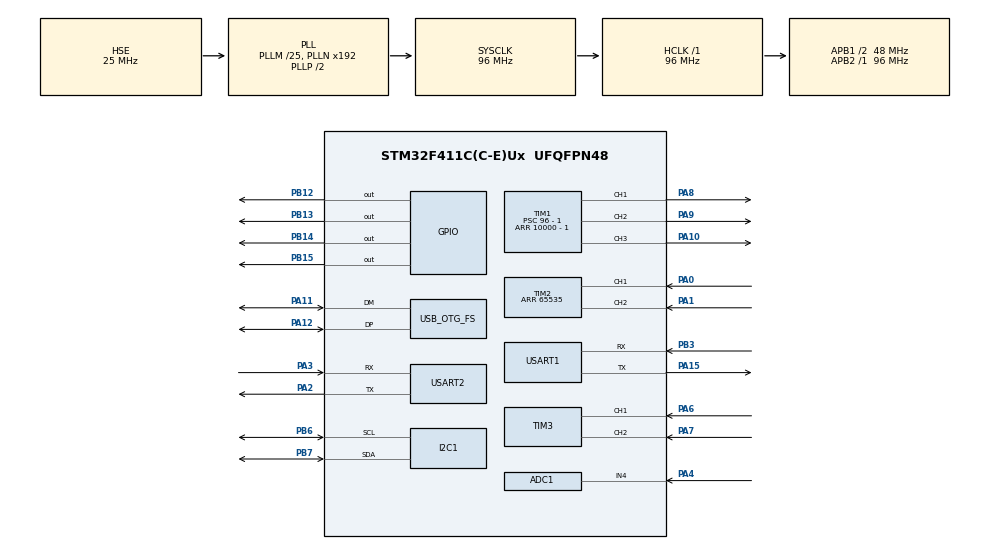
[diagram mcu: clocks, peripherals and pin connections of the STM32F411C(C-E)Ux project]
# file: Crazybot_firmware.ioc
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ADC1.Channel-0\#ChannelRegularConversion=ADC_CHANNEL_4
ADC1.NbrOfConversionFlag=1
ADC1.Rank-0\#ChannelRegularConversion=1
ADC1.SamplingTime-0\#ChannelRegularConversion=ADC_SAMPLETIME_3CYCLES
ADC1.master=1
I2C1.I2C_Mode=I2C_Fast
Mcu.Family=STM32F4
Mcu.Name=STM32F411C(C-E)Ux
Mcu.Package=UFQFPN48
NVIC.PriorityGroup=NVIC_PRIORITYGROUP_4
PA0-WKUP.Signal=S_TIM2_CH1_ETR
PA1.Signal=S_TIM2_CH2
PA10.Signal=S_TIM1_CH3
PA11.Mode=Device_Only
PA11.Signal=USB_OTG_FS_DM
PA12.Mode=Device_Only
PA12.Signal=USB_OTG_FS_DP
PA13.Mode=Serial_Wire
PA13.Signal=SYS_JTMS-SWDIO
PA14.Mode=Serial_Wire
PA14.Signal=SYS_JTCK-SWCLK
PA15.Mode=Asynchronous
PA15.Signal=USART1_TX
PA2.Mode=Asynchronous
PA2.Signal=USART2_TX
PA3.Mode=Asynchronous
PA3.Signal=USART2_RX
PA4.Signal=ADCx_IN4
PA6.Signal=S_TIM3_CH1
PA7.Signal=S_TIM3_CH2
PA8.Signal=S_TIM1_CH1
PA9.Signal=S_TIM1_CH2
PB12.Signal=GPIO_Output
PB13.Signal=GPIO_Output
PB14.Signal=GPIO_Output
PB15.Signal=GPIO_Output
PB3.Mode=Asynchronous
PB3.Signal=USART1_RX
PB6.Mode=I2C
PB6.Signal=I2C1_SCL
PB7.Mode=I2C
PB7.Signal=I2C1_SDA
PH0\ -\ OSC_IN.Mode=HSE-External-Oscillator
PH0\ -\ OSC_IN.Signal=RCC_OSC_IN
PH1\ -\ OSC_OUT.Mode=HSE-External-Oscillator
PH1\ -\ OSC_OUT.Signal=RCC_OSC_OUT
ProjectManager.HeapSize=0x200
ProjectManager.StackSize=0x400
ProjectManager.TargetToolchain=Makefile
RCC.48MHZClocksFreq_Value=48000000
RCC.AHBFreq_Value=96000000
RCC.APB1CLKDivider=RCC_HCLK_DIV2
RCC.APB1Freq_Value=48000000
RCC.APB1TimFreq_Value=96000000
RCC.APB2Freq_Value=96000000
RCC.APB2TimFreq_Value=96000000
RCC.CortexFreq_Value=96000000
RCC.HCLKFreq_Value=96000000
RCC.HSE_VALUE=25000000
RCC.HSI_VALUE=16000000
RCC.LSE_VALUE=32768
RCC.PLLM=25
RCC.SYSCLKFreq_VALUE=96000000
RCC.SYSCLKSource=RCC_SYSCLKSOURCE_PLLCLK
RCC.VCOOutputFreq_Value=192000000
SH.ADCx_IN4.0=ADC1_IN4,IN4
SH.S_TIM1_CH1.0=TIM1_CH1,PWM Generation1 CH1
SH.S_TIM1_CH2.0=TIM1_CH2,PWM Generation2 CH2
SH.S_TIM1_CH3.0=TIM1_CH3,PWM Generation3 CH3
SH.S_TIM2_CH1_ETR.0=TIM2_CH1,Encoder_Interface
SH.S_TIM2_CH2.0=TIM2_CH2,Encoder_Interface
SH.S_TIM3_CH1.0=TIM3_CH1,Encoder_Interface
SH.S_TIM3_CH2.0=TIM3_CH2,Encoder_Interface
TIM1.Channel-PWM\ Generation1\ CH1=TIM_CHANNEL_1
TIM1.Channel-PWM\ Generation2\ CH2=TIM_CHANNEL_2
TIM1.Channel-PWM\ Generation3\ CH3=TIM_CHANNEL_3
TIM1.Period=10000 - 1
TIM1.Prescaler=96 - 1
TIM2.EncoderMode=TIM_ENCODERMODE_TI12
TIM2.IC1Filter=15
TIM2.IC2Filter=15
TIM2.Period=65535
TIM3.EncoderMode=TIM_ENCODERMODE_TI12
TIM3.IC1Filter=15
TIM3.IC2Filter=15
USART1.VirtualMode=VM_ASYNC
USART2.VirtualMode=VM_ASYNC
USB_OTG_FS.VirtualMode=Device_Only
VP_TIM1_VS_ClockSourceINT.Mode=Internal
board=custom

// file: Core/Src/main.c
/* USER CODE BEGIN Header */
/**
  ******************************************************************************
  * @file           : main.c
  * @brief          : Main program body
  ******************************************************************************
  * @attention
  *
  * Copyright (c) 2023 STMicroelectronics.
  * All rights reserved.
  *
  * This software is licensed under terms that can be found in the LICENSE file
  * in the root directory of this software component.
  * If no LICENSE file comes with this software, it is provided AS-IS.
  *
  ******************************************************************************
  */
/* USER CODE END Header */
#include "main.h"
#include "adc.h"
#include "i2c.h"
#include "tim.h"
#include "usart.h"
#include "usb_otg.h"
#include "gpio.h"

/* USER CODE BEGIN Includes */
#include <stdio.h>
/* USER CODE END Includes */

void SystemClock_Config(void);

int main(void)
{

  /* MCU Configuration--------------------------------------------------------*/

  /* Reset of all peripherals, Initializes the Flash interface and the Systick. */
  HAL_Init();

  /* Configure the system clock */
  SystemClock_Config();

  /* Initialize all configured peripherals */
  MX_GPIO_Init();
  MX_I2C1_Init();
  MX_TIM1_Init();
  MX_TIM2_Init();
  MX_TIM3_Init();
  MX_USART1_UART_Init();
  MX_USART2_UART_Init();
  MX_USB_OTG_FS_PCD_Init();
  MX_ADC1_Init();
  /* USER CODE BEGIN 2 */
  printf("Hello world from crazybot!\r\n");
  /* USER CODE END 2 */

  /* Infinite loop */
  while (1)
  {

    /* USER CODE BEGIN 3 */
    HAL_Delay(1000);
  }
  /* USER CODE END 3 */
}

void SystemClock_Config(void)
{
  RCC_OscInitTypeDef RCC_OscInitStruct = {0};
  RCC_ClkInitTypeDef RCC_ClkInitStruct = {0};

  /** Configure the main internal regulator output voltage
  */
  __HAL_RCC_PWR_CLK_ENABLE();
  __HAL_PWR_VOLTAGESCALING_CONFIG(PWR_REGULATOR_VOLTAGE_SCALE1);

  /** Initializes the RCC Oscillators according to the specified parameters
  * in the RCC_OscInitTypeDef structure.
  */
  RCC_OscInitStruct.OscillatorType = RCC_OSCILLATORTYPE_HSE;
  RCC_OscInitStruct.HSEState = RCC_HSE_ON;
  RCC_OscInitStruct.PLL.PLLState = RCC_PLL_ON;
  RCC_OscInitStruct.PLL.PLLSource = RCC_PLLSOURCE_HSE;
  RCC_OscInitStruct.PLL.PLLM = 25;
  RCC_OscInitStruct.PLL.PLLN = 192;
  RCC_OscInitStruct.PLL.PLLP = RCC_PLLP_DIV2;
  RCC_OscInitStruct.PLL.PLLQ = 4;
  if (HAL_RCC_OscConfig(&RCC_OscInitStruct) != HAL_OK)
  {
    Error_Handler();
  }

  /** Initializes the CPU, AHB and APB buses clocks
  */
  RCC_ClkInitStruct.ClockType = RCC_CLOCKTYPE_HCLK|RCC_CLOCKTYPE_SYSCLK
                              |RCC_CLOCKTYPE_PCLK1|RCC_CLOCKTYPE_PCLK2;
  RCC_ClkInitStruct.SYSCLKSource = RCC_SYSCLKSOURCE_PLLCLK;
  RCC_ClkInitStruct.AHBCLKDivider = RCC_SYSCLK_DIV1;
  RCC_ClkInitStruct.APB1CLKDivider = RCC_HCLK_DIV2;
  RCC_ClkInitStruct.APB2CLKDivider = RCC_HCLK_DIV1;

  if (HAL_RCC_ClockConfig(&RCC_ClkInitStruct, FLASH_LATENCY_3) != HAL_OK)
  {
    Error_Handler();
  }
}

/* USER CODE BEGIN 4 */
int _write(int fd, char *ptr, int len)
{
  HAL_UART_Transmit(&huart1, (uint8_t*)ptr, len, 0xFFFF);
  return len;
}
/* USER CODE END 4 */

void Error_Handler(void)
{
  __disable_irq();
  while (1)
  {
  }
}
